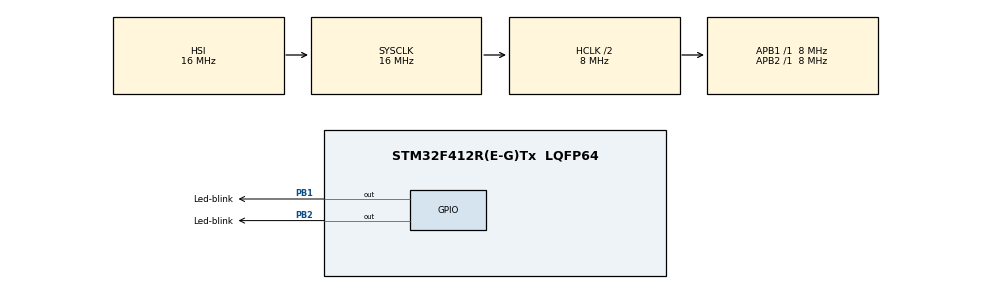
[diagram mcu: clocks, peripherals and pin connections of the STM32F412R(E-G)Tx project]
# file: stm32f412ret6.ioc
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Mcu.Family=STM32F4
Mcu.Name=STM32F412R(E-G)Tx
Mcu.Package=LQFP64
NVIC.PriorityGroup=NVIC_PRIORITYGROUP_4
PA13.Mode=Serial_Wire
PA13.Signal=SYS_JTMS-SWDIO
PA14.Mode=Serial_Wire
PA14.Signal=SYS_JTCK-SWCLK
PB1.GPIO_Label=Led-blink
PB1.GPIO_ModeDefaultOutputPP=GPIO_MODE_OUTPUT_PP
PB1.GPIO_PuPd=GPIO_NOPULL
PB1.GPIO_Speed=GPIO_SPEED_FREQ_HIGH
PB1.PinState=GPIO_PIN_SET
PB1.Signal=GPIO_Output
PB2.GPIO_Label=Led-blink
PB2.GPIO_ModeDefaultOutputPP=GPIO_MODE_OUTPUT_PP
PB2.GPIO_PuPd=GPIO_NOPULL
PB2.GPIO_Speed=GPIO_SPEED_FREQ_HIGH
PB2.PinState=GPIO_PIN_SET
PB2.Signal=GPIO_Output
PH0\ -\ OSC_IN.Mode=HSE-External-Oscillator
PH0\ -\ OSC_IN.Signal=RCC_OSC_IN
PH1\ -\ OSC_OUT.Mode=HSE-External-Oscillator
PH1\ -\ OSC_OUT.Signal=RCC_OSC_OUT
ProjectManager.HeapSize=0x200
ProjectManager.StackSize=0x400
ProjectManager.TargetToolchain=MDK-ARM V5.32
RCC.AHBCLKDivider=RCC_SYSCLK_DIV2
RCC.AHBFreq_Value=8000000
RCC.APB1Freq_Value=8000000
RCC.APB1TimFreq_Value=8000000
RCC.APB2Freq_Value=8000000
RCC.APB2TimFreq_Value=8000000
RCC.CortexFreq_Value=8000000
RCC.HCLKFreq_Value=8000000
RCC.HSE_VALUE=8000000
RCC.PLLSourceVirtual=RCC_PLLSOURCE_HSE
RCC.SYSCLKFreq_VALUE=16000000
RCC.USBFreq_Value=48000000
RCC.VCOOutputFreq_Value=96000000
board=custom

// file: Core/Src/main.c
/* USER CODE BEGIN Header */
/**
  ******************************************************************************
  * @file           : main.c
  * @brief          : Main program body
  ******************************************************************************
  * @attention
  *
  * Copyright (c) 2025 STMicroelectronics.
  * All rights reserved.
  *
  * This software is licensed under terms that can be found in the LICENSE file
  * in the root directory of this software component.
  * If no LICENSE file comes with this software, it is provided AS-IS.
  *
  ******************************************************************************
  */
/* USER CODE END Header */
#include "main.h"

/* USER CODE BEGIN Includes */
#include <string.h>
#include <stdio.h>
/* USER CODE END Includes */

void SystemClock_Config(void);
static void MX_GPIO_Init(void);

/* USER CODE BEGIN 0 */
// function must add void return because C will treat default as INT return, maybe error
void test(void);

/* USER CODE END 0 */

int main(void)
{

  /* MCU Configuration--------------------------------------------------------*/

  /* Reset of all peripherals, Initializes the Flash interface and the Systick. */
  HAL_Init();

  /* Configure the system clock */
  SystemClock_Config();

  /* Initialize all configured peripherals */
  MX_GPIO_Init();

  /* Infinite loop */
  while (1)
  {

    /* USER CODE BEGIN 3 */
		test();
		HAL_Delay(300);

  }
  /* USER CODE END 3 */
}

void SystemClock_Config(void)
{
  RCC_OscInitTypeDef RCC_OscInitStruct = {0};
  RCC_ClkInitTypeDef RCC_ClkInitStruct = {0};

  /** Configure the main internal regulator output voltage
  */
  __HAL_RCC_PWR_CLK_ENABLE();
  __HAL_PWR_VOLTAGESCALING_CONFIG(PWR_REGULATOR_VOLTAGE_SCALE1);

  /** Initializes the RCC Oscillators according to the specified parameters
  * in the RCC_OscInitTypeDef structure.
  */
  RCC_OscInitStruct.OscillatorType = RCC_OSCILLATORTYPE_HSI;
  RCC_OscInitStruct.HSIState = RCC_HSI_ON;
  RCC_OscInitStruct.HSICalibrationValue = RCC_HSICALIBRATION_DEFAULT;
  RCC_OscInitStruct.PLL.PLLState = RCC_PLL_NONE;
  if (HAL_RCC_OscConfig(&RCC_OscInitStruct) != HAL_OK)
  {
    Error_Handler();
  }

  /** Initializes the CPU, AHB and APB buses clocks
  */
  RCC_ClkInitStruct.ClockType = RCC_CLOCKTYPE_HCLK|RCC_CLOCKTYPE_SYSCLK
                              |RCC_CLOCKTYPE_PCLK1|RCC_CLOCKTYPE_PCLK2;
  RCC_ClkInitStruct.SYSCLKSource = RCC_SYSCLKSOURCE_HSI;
  RCC_ClkInitStruct.AHBCLKDivider = RCC_SYSCLK_DIV2;
  RCC_ClkInitStruct.APB1CLKDivider = RCC_HCLK_DIV1;
  RCC_ClkInitStruct.APB2CLKDivider = RCC_HCLK_DIV1;

  if (HAL_RCC_ClockConfig(&RCC_ClkInitStruct, FLASH_LATENCY_0) != HAL_OK)
  {
    Error_Handler();
  }
}

static void MX_GPIO_Init(void)
{
  GPIO_InitTypeDef GPIO_InitStruct = {0};

  /* GPIO Ports Clock Enable */
  __HAL_RCC_GPIOH_CLK_ENABLE();
  __HAL_RCC_GPIOB_CLK_ENABLE();
  __HAL_RCC_GPIOA_CLK_ENABLE();

  /*Configure GPIO pin Output Level */
  HAL_GPIO_WritePin(GPIOB, Led_blink_Pin|Led_blinkB2_Pin, GPIO_PIN_SET);

  /*Configure GPIO pins : Led_blink_Pin Led_blinkB2_Pin */
  GPIO_InitStruct.Pin = Led_blink_Pin|Led_blinkB2_Pin;
  GPIO_InitStruct.Mode = GPIO_MODE_OUTPUT_PP;
  GPIO_InitStruct.Pull = GPIO_NOPULL;
  GPIO_InitStruct.Speed = GPIO_SPEED_FREQ_HIGH;
  HAL_GPIO_Init(GPIOB, &GPIO_InitStruct);

}

/* USER CODE BEGIN 4 */
// coding must be inside this block comment for compiler insert into Flash memory
void test(void) {
	// this function will be optimized and cannot debug in main.c, must to debug in Disassembly windows above ^
	HAL_GPIO_TogglePin(GPIOB, GPIO_PIN_1 | GPIO_PIN_2);
	// some unused code will be optimized and removed out of main.c
}
/* USER CODE END 4 */

void Error_Handler(void)
{
  __disable_irq();
  while (1)
  {
  }
}
